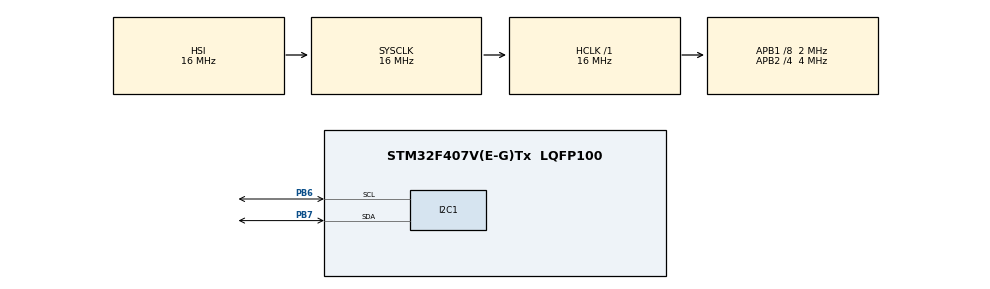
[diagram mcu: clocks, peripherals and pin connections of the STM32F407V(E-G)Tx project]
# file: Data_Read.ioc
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I2C1.I2C_Mode=I2C_Standard
Mcu.Family=STM32F4
Mcu.Name=STM32F407V(E-G)Tx
Mcu.Package=LQFP100
NVIC.PriorityGroup=NVIC_PRIORITYGROUP_0
PB6.GPIO_Pu=GPIO_PULLUP
PB6.GPIO_Speed=GPIO_SPEED_FREQ_LOW
PB6.Mode=I2C
PB6.Signal=I2C1_SCL
PB7.GPIO_Pu=GPIO_PULLUP
PB7.GPIO_Speed=GPIO_SPEED_FREQ_LOW
PB7.Mode=I2C
PB7.Signal=I2C1_SDA
ProjectManager.HeapSize=0x200
ProjectManager.StackSize=0x400
ProjectManager.TargetToolchain=STM32CubeIDE
RCC.48MHZClocksFreq_Value=14285714.285714285
RCC.AHBFreq_Value=16000000
RCC.APB1CLKDivider=RCC_HCLK_DIV8
RCC.APB1Freq_Value=2000000
RCC.APB1TimFreq_Value=4000000
RCC.APB2CLKDivider=RCC_HCLK_DIV4
RCC.APB2Freq_Value=4000000
RCC.APB2TimFreq_Value=8000000
RCC.CortexFreq_Value=16000000
RCC.HCLKFreq_Value=16000000
RCC.HSE_VALUE=8000000
RCC.HSI_VALUE=16000000
RCC.PLLM=8
RCC.PLLN=50
RCC.PLLQ=7
RCC.SYSCLKFreq_VALUE=16000000
RCC.VCOOutputFreq_Value=100000000
board=STM32F407G-DISC1

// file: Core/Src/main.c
/* USER CODE BEGIN Header */
/**
  ******************************************************************************
  * @file           : main.c
  * @brief          : Main program body
  ******************************************************************************
  * @attention
  *
  * Copyright (c) 2026 STMicroelectronics.
  * All rights reserved.
  *
  * This software is licensed under terms that can be found in the LICENSE file
  * in the root directory of this software component.
  * If no LICENSE file comes with this software, it is provided AS-IS.
  *
  ******************************************************************************
  */
/* USER CODE END Header */
#include "main.h"

I2C_HandleTypeDef hi2c1;

/* USER CODE BEGIN PV */
#define MPU6050_ADDR 0xD0  // 0x68 << 1
#define INA226_ADDR  0x88  // 0x40 << 1

// MPU6050 Registers
#define MPU6050_REG_PWR_MGMT_1 0x6B
#define MPU6050_REG_ACCEL_XOUT_H 0x3B

// INA226 Registers
#define INA226_REG_CONFIG        0x00
#define INA226_REG_BUS_VOLTAGE   0x02
#define INA226_REG_CURRENT       0x04
#define INA226_REG_CALIBRATION   0x05

uint8_t mpu_data[6];
float accel_x, accel_y, accel_z;
float accel_g_x, accel_g_y, accel_g_z;

// INA226 Variables
uint8_t ina_data[2];
int16_t bus_voltage_raw;
float bus_voltage_V;       // Tracks Voltage in Volts
int16_t current_raw;
float current_mA;          // Tracks Current in milliamps
/* USER CODE END PV */

void SystemClock_Config(void);
static void MX_GPIO_Init(void);
static void MX_I2C1_Init(void);

int main(void)
{

  /* MCU Configuration--------------------------------------------------------*/

  /* Reset of all peripherals, Initializes the Flash interface and the Systick. */
  HAL_Init();

  /* Configure the system clock */
  SystemClock_Config();

  /* Initialize all configured peripherals */
  MX_GPIO_Init();
  MX_I2C1_Init();
  /* USER CODE BEGIN 2 */
  uint8_t mpu_reset = 0x80;
  HAL_I2C_Mem_Write(&hi2c1, MPU6050_ADDR, 0x6B, 1, &mpu_reset, 1, 100);
  // 1. Wake up MPU6050
  uint8_t wake_up = 0x00;
  HAL_I2C_Mem_Write(&hi2c1, MPU6050_ADDR, MPU6050_REG_PWR_MGMT_1, 1, &wake_up, 1, 100);

  // 2. Configure and Calibrate INA226
  // Write Configuration: 0x4127 (Default: 16 averages, 1.1ms conversion time, continuous mode)
  uint8_t ina_config[2] = {0x41, 0x27};
  HAL_I2C_Mem_Write(&hi2c1, INA226_ADDR, INA226_REG_CONFIG, 1, ina_config, 2, 100);

  // Write Calibration: 0x0200 (Sets Current LSB to 0.1mA for a 0.1 Ohm shunt)
  uint8_t ina226_cal[2] = {0x02, 0x00};
  HAL_I2C_Mem_Write(&hi2c1, INA226_ADDR, INA226_REG_CALIBRATION, 1, ina226_cal, 2, 100);
  // Brief delay to allow sensors to settle
  HAL_Delay(50);
  /* USER CODE END 2 */

  /* Infinite loop */
  while (1)
  {

	  // ---------------------------------------------------------
	  // 1. READ MPU6050 (Vibration / Acceleration)
	  // ---------------------------------------------------------
	  HAL_I2C_Mem_Read(&hi2c1, MPU6050_ADDR, MPU6050_REG_ACCEL_XOUT_H, 1, mpu_data, 6, 100);
	  accel_x = (int16_t)(mpu_data[0] << 8 | mpu_data[1]);
	  accel_y = (int16_t)(mpu_data[2] << 8 | mpu_data[3]);
	  accel_z = (int16_t)(mpu_data[4] << 8 | mpu_data[5]);

	  accel_g_x = accel_x / 16384.0f;
	  accel_g_y = accel_y / 16384.0f;
	  accel_g_z = accel_z / 16384.0f;

	  // ---------------------------------------------------------
	  // 2. READ INA226 (Current)
	  // ---------------------------------------------------------
	  HAL_I2C_Mem_Read(&hi2c1, INA226_ADDR, INA226_REG_CURRENT, 1, ina_data, 2, 100);
	  current_raw = (int16_t)(ina_data[0] << 8 | ina_data[1]);

	  // With a 0x1000 calibration, the current LSB is 0.1mA
	  current_mA = current_raw * 0.0125f;

	  // Sample rate delay (Adjust based on how fast you want CubeMonitor to plot)
	  HAL_Delay(10);

  }
}

void SystemClock_Config(void)
{
  RCC_OscInitTypeDef RCC_OscInitStruct = {0};
  RCC_ClkInitTypeDef RCC_ClkInitStruct = {0};

  /** Configure the main internal regulator output voltage
  */
  __HAL_RCC_PWR_CLK_ENABLE();
  __HAL_PWR_VOLTAGESCALING_CONFIG(PWR_REGULATOR_VOLTAGE_SCALE1);

  /** Initializes the RCC Oscillators according to the specified parameters
  * in the RCC_OscInitTypeDef structure.
  */
  RCC_OscInitStruct.OscillatorType = RCC_OSCILLATORTYPE_HSI;
  RCC_OscInitStruct.HSIState = RCC_HSI_ON;
  RCC_OscInitStruct.HSICalibrationValue = RCC_HSICALIBRATION_DEFAULT;
  RCC_OscInitStruct.PLL.PLLState = RCC_PLL_NONE;
  if (HAL_RCC_OscConfig(&RCC_OscInitStruct) != HAL_OK)
  {
    Error_Handler();
  }

  /** Initializes the CPU, AHB and APB buses clocks
  */
  RCC_ClkInitStruct.ClockType = RCC_CLOCKTYPE_HCLK|RCC_CLOCKTYPE_SYSCLK
                              |RCC_CLOCKTYPE_PCLK1|RCC_CLOCKTYPE_PCLK2;
  RCC_ClkInitStruct.SYSCLKSource = RCC_SYSCLKSOURCE_HSI;
  RCC_ClkInitStruct.AHBCLKDivider = RCC_SYSCLK_DIV1;
  RCC_ClkInitStruct.APB1CLKDivider = RCC_HCLK_DIV8;
  RCC_ClkInitStruct.APB2CLKDivider = RCC_HCLK_DIV4;

  if (HAL_RCC_ClockConfig(&RCC_ClkInitStruct, FLASH_LATENCY_0) != HAL_OK)
  {
    Error_Handler();
  }
}

static void MX_I2C1_Init(void)
{

  hi2c1.Instance = I2C1;
  hi2c1.Init.ClockSpeed = 100000;
  hi2c1.Init.DutyCycle = I2C_DUTYCYCLE_2;
  hi2c1.Init.OwnAddress1 = 0;
  hi2c1.Init.AddressingMode = I2C_ADDRESSINGMODE_7BIT;
  hi2c1.Init.DualAddressMode = I2C_DUALADDRESS_DISABLE;
  hi2c1.Init.OwnAddress2 = 0;
  hi2c1.Init.GeneralCallMode = I2C_GENERALCALL_DISABLE;
  hi2c1.Init.NoStretchMode = I2C_NOSTRETCH_DISABLE;
  if (HAL_I2C_Init(&hi2c1) != HAL_OK)
  {
    Error_Handler();
  }

}

static void MX_GPIO_Init(void)
{

  /* GPIO Ports Clock Enable */
  __HAL_RCC_GPIOB_CLK_ENABLE();

}

void Error_Handler(void)
{
  __disable_irq();
  while (1)
  {
  }
}
